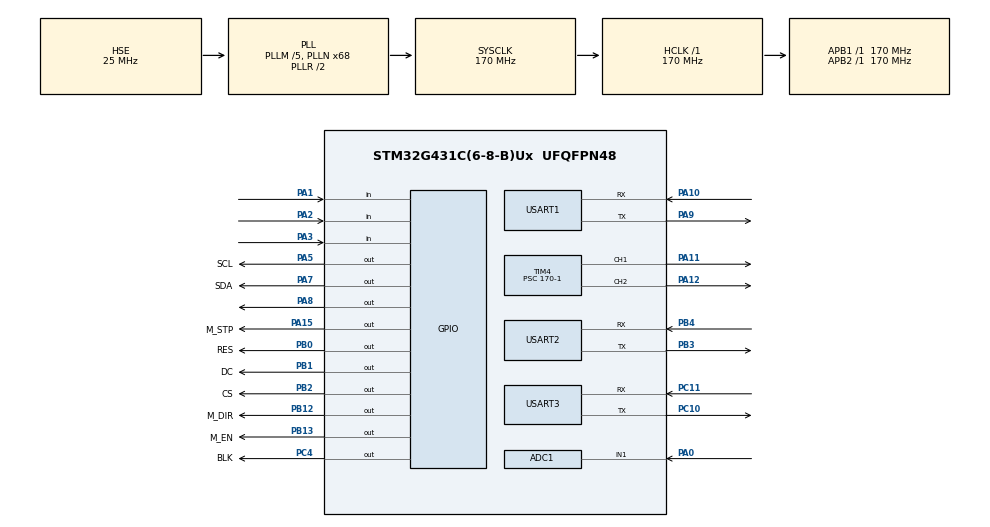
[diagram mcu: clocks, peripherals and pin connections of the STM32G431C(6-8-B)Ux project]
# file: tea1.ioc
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ADC1.Channel-0\#ChannelRegularConversion=ADC_CHANNEL_1
ADC1.ContinuousConvMode=ENABLE
ADC1.NbrOfConversionFlag=1
ADC1.OffsetNumber-0\#ChannelRegularConversion=ADC_OFFSET_NONE
ADC1.Rank-0\#ChannelRegularConversion=1
ADC1.SamplingTime-0\#ChannelRegularConversion=ADC_SAMPLETIME_2CYCLES_5
ADC1.master=1
Mcu.Family=STM32G4
Mcu.Name=STM32G431C(6-8-B)Ux
Mcu.Package=UFQFPN48
NVIC.PriorityGroup=NVIC_PRIORITYGROUP_4
NVIC.TIM1_TRG_COM_TIM17_IRQn=true\:1\:0\:true\:false\:true\:true\:true\:true
PA0.Mode=IN1-Single-Ended
PA0.Signal=ADC1_IN1
PA1.GPIO_PuPd=GPIO_PULLUP
PA1.Signal=GPIO_Input
PA10.Mode=Asynchronous
PA10.Signal=USART1_RX
PA11.GPIO_Speed=GPIO_SPEED_FREQ_HIGH
PA11.Signal=S_TIM4_CH1
PA12.GPIO_Speed=GPIO_SPEED_FREQ_HIGH
PA12.Signal=S_TIM4_CH2
PA13.Mode=Serial_Wire
PA13.Signal=SYS_JTMS-SWDIO
PA14.Mode=Serial_Wire
PA14.Signal=SYS_JTCK-SWCLK
PA15.GPIO_Label=M_STP
PA15.GPIO_Speed=GPIO_SPEED_FREQ_VERY_HIGH
PA15.Signal=GPIO_Output
PA2.GPIO_PuPd=GPIO_PULLUP
PA2.Signal=GPIO_Input
PA3.GPIO_PuPd=GPIO_PULLUP
PA3.Signal=GPIO_Input
PA5.GPIO_Label=SCL
PA5.GPIO_Speed=GPIO_SPEED_FREQ_VERY_HIGH
PA5.Signal=GPIO_Output
PA7.GPIO_Label=SDA
PA7.GPIO_Speed=GPIO_SPEED_FREQ_VERY_HIGH
PA7.Signal=GPIO_Output
PA8.Signal=GPIO_Output
PA9.Mode=Asynchronous
PA9.Signal=USART1_TX
PB0.GPIO_Label=RES
PB0.GPIO_Speed=GPIO_SPEED_FREQ_HIGH
PB0.Signal=GPIO_Output
PB1.GPIO_Label=DC
PB1.GPIO_Speed=GPIO_SPEED_FREQ_VERY_HIGH
PB1.Signal=GPIO_Output
PB12.GPIO_Label=M_DIR
PB12.GPIO_Speed=GPIO_SPEED_FREQ_HIGH
PB12.Signal=GPIO_Output
PB13.GPIO_Label=M_EN
PB13.GPIO_Speed=GPIO_SPEED_FREQ_HIGH
PB13.Signal=GPIO_Output
PB2.GPIO_Label=CS
PB2.GPIO_Speed=GPIO_SPEED_FREQ_VERY_HIGH
PB2.Signal=GPIO_Output
PB3.Mode=Asynchronous
PB3.Signal=USART2_TX
PB4.Mode=Asynchronous
PB4.Signal=USART2_RX
PC10.Mode=Asynchronous
PC10.Signal=USART3_TX
PC11.Mode=Asynchronous
PC11.Signal=USART3_RX
PC4.GPIO_Label=BLK
PC4.GPIO_Speed=GPIO_SPEED_FREQ_HIGH
PC4.Signal=GPIO_Output
PF0-OSC_IN.Mode=HSE-External-Oscillator
PF0-OSC_IN.Signal=RCC_OSC_IN
PF1-OSC_OUT.Mode=HSE-External-Oscillator
PF1-OSC_OUT.Signal=RCC_OSC_OUT
ProjectManager.HeapSize=0x200
ProjectManager.StackSize=0x400
ProjectManager.TargetToolchain=MDK-ARM V5.32
RCC.ADC12Freq_Value=170000000
RCC.AHBFreq_Value=170000000
RCC.APB1Freq_Value=170000000
RCC.APB1TimFreq_Value=170000000
RCC.APB2Freq_Value=170000000
RCC.APB2TimFreq_Value=170000000
RCC.CortexFreq_Value=170000000
RCC.EXTERNAL_CLOCK_VALUE=12288000
RCC.HCLKFreq_Value=170000000
RCC.HSE_VALUE=25000000
RCC.HSI48_VALUE=48000000
RCC.HSI_VALUE=16000000
RCC.LSE_VALUE=32768
RCC.PLLM=RCC_PLLM_DIV5
RCC.PLLN=68
RCC.PLLSourceVirtual=RCC_PLLSOURCE_HSE
RCC.SYSCLKFreq_VALUE=170000000
RCC.SYSCLKSource=RCC_SYSCLKSOURCE_PLLCLK
RCC.USBFreq_Value=170000000
RCC.VCOOutputFreq_Value=340000000
SH.S_TIM4_CH1.0=TIM4_CH1,PWM Generation1 CH1
SH.S_TIM4_CH2.0=TIM4_CH2,PWM Generation2 CH2
TIM17.PeriodNoDither=1000-1
TIM17.Prescaler=170-1
TIM4.Channel-PWM\ Generation1\ CH1=TIM_CHANNEL_1
TIM4.Channel-PWM\ Generation2\ CH2=TIM_CHANNEL_2
TIM4.PeriodNoDither=20000-1
TIM4.Prescaler=170-1
USART1.VirtualMode-Asynchronous=VM_ASYNC
USART2.VirtualMode-Asynchronous=VM_ASYNC
USART3.VirtualMode-Asynchronous=VM_ASYNC
VP_SYS_VS_DBSignals.Mode=DisableDeadBatterySignals
VP_TIM17_VS_ClockSourceINT.Mode=Enable_Timer
board=custom

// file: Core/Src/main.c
/* USER CODE BEGIN Header */
/**
  ******************************************************************************
  * @file           : main.c
  * @brief          : Main program body
  ******************************************************************************
  * @attention
  *
  * Copyright (c) 2024 STMicroelectronics.
  * All rights reserved.
  *
  * This software is licensed under terms that can be found in the LICENSE file
  * in the root directory of this software component.
  * If no LICENSE file comes with this software, it is provided AS-IS.
  *
  ******************************************************************************
  */
/* USER CODE END Header */
#include "main.h"
#include "adc.h"
#include "tim.h"
#include "usart.h"
#include "gpio.h"

/* USER CODE BEGIN Includes */

#include "app.h"
#include "commond.h"

//#include <stdio.h>

/* USER CODE END Includes */

void SystemClock_Config(void);

/* USER CODE BEGIN 0 */

//void lv_example_led_1(void);

/* USER CODE END 0 */

int main(void)
{
  /* USER CODE BEGIN 1 */

	float angle_val = 0;

  /* USER CODE END 1 */

  /* MCU Configuration--------------------------------------------------------*/

  /* Reset of all peripherals, Initializes the Flash interface and the Systick. */
  HAL_Init();

  /* Configure the system clock */
  SystemClock_Config();

  /* Initialize all configured peripherals */
  MX_GPIO_Init();
  MX_USART1_UART_Init();
  MX_TIM17_Init();
  MX_USART2_UART_Init();
  MX_USART3_UART_Init();
  MX_ADC1_Init();
  MX_TIM4_Init();
  /* USER CODE BEGIN 2 */
	// ����ADC
//	HAL_ADC_Start(&hadc1);
//	// ��ʼ��ѯת��
//	HAL_ADC_PollForConversion(&hadc1,100);
//
//	key_driver_init();
//	adc_driver_init();
//
////  beep_SetFreq(1000);
////  beep_on(mode1);
//
	HAL_TIM_Base_Start_IT(&htim17); //1ms
	printf("OK!\r\n");

	HAL_TIM_PWM_Start(&htim4, TIM_CHANNEL_1);   //���
	HAL_TIM_PWM_Start(&htim4, TIM_CHANNEL_2);

//	unsigned char i=0;
//	LCD_Init();
//	LCD_Fill(0,0,lcddev.width,lcddev.height,BLACK);
//	LCD_ShowString(18,30,"LuatOS",WHITE,BLUE,0);
//	lv_init();
//	lv_port_disp_init();
//	lv_example_led_1();

  /* USER CODE END 2 */

  /* Infinite loop */
  /* USER CODE BEGIN WHILE */
  while (1)
  {
//	  printf("1\r");
//	  lv_task_handler();
//	  beep_run();
//	  vofa_start();

//		main_test(); 		//����������

//	  HAL_GPIO_WritePin(M_EN_GPIO_Port, M_EN_Pin, GPIO_PIN_SET);
//	  HAL_GPIO_WritePin(M_DIR_GPIO_Port, M_DIR_Pin, GPIO_PIN_SET);
//	  GPIO_OutputPulses(3200, 1000); //  (1kHz)
////	  printf("Forware\r\n");
//
//	  HAL_Delay(1000);
//
////	  HAL_GPIO_WritePin(M_EN_GPIO_Port, M_EN_Pin, GPIO_PIN_SET);
//	  HAL_GPIO_WritePin(M_DIR_GPIO_Port, M_DIR_Pin, GPIO_PIN_RESET);
//	  GPIO_OutputPulses(1600, 1000); //  (1kHz)
////	  printf("Hard\r\n");
//	  HAL_Delay(1000);

	  Servo_SetAngle(servo1, angle_val);
	  Servo_SetAngle(servo2, angle_val);
    /* USER CODE END WHILE */

  }
}

void SystemClock_Config(void)
{
  RCC_OscInitTypeDef RCC_OscInitStruct = {0};
  RCC_ClkInitTypeDef RCC_ClkInitStruct = {0};

  /** Configure the main internal regulator output voltage
  */
  HAL_PWREx_ControlVoltageScaling(PWR_REGULATOR_VOLTAGE_SCALE1_BOOST);

  /** Initializes the RCC Oscillators according to the specified parameters
  * in the RCC_OscInitTypeDef structure.
  */
  RCC_OscInitStruct.OscillatorType = RCC_OSCILLATORTYPE_HSE;
  RCC_OscInitStruct.HSEState = RCC_HSE_ON;
  RCC_OscInitStruct.PLL.PLLState = RCC_PLL_ON;
  RCC_OscInitStruct.PLL.PLLSource = RCC_PLLSOURCE_HSE;
  RCC_OscInitStruct.PLL.PLLM = RCC_PLLM_DIV5;
  RCC_OscInitStruct.PLL.PLLN = 68;
  RCC_OscInitStruct.PLL.PLLP = RCC_PLLP_DIV2;
  RCC_OscInitStruct.PLL.PLLQ = RCC_PLLQ_DIV2;
  RCC_OscInitStruct.PLL.PLLR = RCC_PLLR_DIV2;
  if (HAL_RCC_OscConfig(&RCC_OscInitStruct) != HAL_OK)
  {
    Error_Handler();
  }

  /** Initializes the CPU, AHB and APB buses clocks
  */
  RCC_ClkInitStruct.ClockType = RCC_CLOCKTYPE_HCLK|RCC_CLOCKTYPE_SYSCLK
                              |RCC_CLOCKTYPE_PCLK1|RCC_CLOCKTYPE_PCLK2;
  RCC_ClkInitStruct.SYSCLKSource = RCC_SYSCLKSOURCE_PLLCLK;
  RCC_ClkInitStruct.AHBCLKDivider = RCC_SYSCLK_DIV1;
  RCC_ClkInitStruct.APB1CLKDivider = RCC_HCLK_DIV1;
  RCC_ClkInitStruct.APB2CLKDivider = RCC_HCLK_DIV1;

  if (HAL_RCC_ClockConfig(&RCC_ClkInitStruct, FLASH_LATENCY_4) != HAL_OK)
  {
    Error_Handler();
  }
}

/* USER CODE BEGIN 4 */

/**
 * LVGLרҵ���Demo
 */
//void lv_example_led_1(void)
//{
//    /*Create a LED and switch it OFF*/
//    lv_obj_t * led1  = lv_led_create(lv_scr_act());
//    lv_obj_align(led1, LV_ALIGN_CENTER, -80, 0);
//    lv_led_off(led1);
//
//    /*Copy the previous LED and set a brightness*/
//    lv_obj_t * led2  = lv_led_create(lv_scr_act());
//    lv_obj_align(led2, LV_ALIGN_CENTER, 0, 0);
//    lv_led_set_brightness(led2, 150);
//    lv_led_set_color(led2, lv_palette_main(LV_PALETTE_RED));
//
//    /*Copy the previous LED and switch it ON*/
//    lv_obj_t * led3  = lv_led_create(lv_scr_act());
//    lv_obj_align(led3, LV_ALIGN_CENTER, 80, 0);
//    lv_led_on(led3);
//}

/* USER CODE END 4 */

void Error_Handler(void)
{
  __disable_irq();
  while (1)
  {
  }
}
